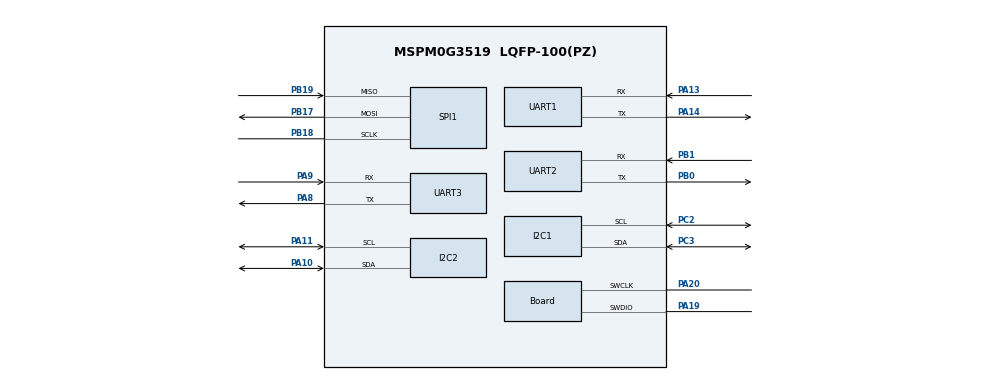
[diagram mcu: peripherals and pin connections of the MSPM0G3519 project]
/**
 * These arguments were used when this file was generated. They will be automatically applied on subsequent loads
 * via the GUI or CLI. Run CLI with '--help' for additional information on how to override these arguments.
 */
//@cliArgs --device "MSPM0G351X" --package "LQFP-100(PZ)" --part "Default"
//@v2CliArgs --device "MSPM0G3519" --package "LQFP-100(PZ)"
// @cliArgs --board /ti/boards/LP_MSPM0G3519 --rtos nortos

/**
 * Import the modules used in this configuration.
 */
const SYSCTL = scripting.addModule("/ti/driverlib/SYSCTL");
const GPIO   = scripting.addModule("/ti/driverlib/GPIO", {}, false);
const UART   = scripting.addModule("/ti/driverlib/UART", {}, false);
const I2C    = scripting.addModule("/ti/driverlib/I2C", {}, false);
const SPI    = scripting.addModule("/ti/driverlib/SPI", {}, false);
const GPIO1  = GPIO.addInstance();
const GPIO2  = GPIO.addInstance();
const GPIO3  = GPIO.addInstance();
const GPIO4  = GPIO.addInstance();
const GPIO5  = GPIO.addInstance();
const GPIO6  = GPIO.addInstance();
const GPIO7  = GPIO.addInstance();
const UART1  = UART.addInstance();
const UART2  = UART.addInstance();
const UART3  = UART.addInstance();
const I2C1   = I2C.addInstance();
const I2C2   = I2C.addInstance();
const SPI1   = SPI.addInstance();

/**
 * Write custom configuration values to the imported modules.
 */
SYSCTL.forceDefaultClkConfig = true;
SYSCTL.clockTreeEn           = true;

GPIO1.$name                          = "GPIO_LED_A";
GPIO1.port                           = "PORTA";
GPIO1.portSegment                    = "Upper";
GPIO1.associatedPins.create(2);
GPIO1.associatedPins[0].$name        = "LED1";
GPIO1.associatedPins[0].direction    = "OUTPUT";
GPIO1.associatedPins[0].initialValue = "SET";
GPIO1.associatedPins[0].assignedPin  = "27";
GPIO1.associatedPins[1].$name        = "LED2";
GPIO1.associatedPins[1].direction    = "OUTPUT";
GPIO1.associatedPins[1].initialValue = "SET";
GPIO1.associatedPins[1].assignedPin  = "26";

GPIO2.$name                          = "GPIO_BUZZER";
GPIO2.port                           = "PORTA";
GPIO2.portSegment                    = "Lower";
GPIO2.associatedPins.create(1);
GPIO2.associatedPins[0].$name        = "BUZZER";
GPIO2.associatedPins[0].direction    = "OUTPUT";
GPIO2.associatedPins[0].initialValue = "CLEARED";
GPIO2.associatedPins[0].assignedPin  = "12";

GPIO3.$name                               = "GPIO_BUTTON_C";
GPIO3.port                                = "PORTC";
GPIO3.portSegment                         = "Lower";
GPIO3.associatedPins.create(1);
GPIO3.associatedPins[0].$name             = "BUTTON1";
GPIO3.associatedPins[0].direction         = "INPUT";
GPIO3.associatedPins[0].internalResistor  = "PULL_UP";
GPIO3.associatedPins[0].assignedPin       = "9";

GPIO4.$name                               = "GPIO_BUTTON_B";
GPIO4.port                                = "PORTB";
GPIO4.portSegment                         = "Upper";
GPIO4.associatedPins.create(2);
GPIO4.associatedPins[0].$name             = "BUTTON2";
GPIO4.associatedPins[0].direction         = "INPUT";
GPIO4.associatedPins[0].internalResistor  = "PULL_UP";
GPIO4.associatedPins[0].assignedPin       = "20";
GPIO4.associatedPins[1].$name             = "BUTTON3";
GPIO4.associatedPins[1].direction         = "INPUT";
GPIO4.associatedPins[1].internalResistor  = "PULL_UP";
GPIO4.associatedPins[1].assignedPin       = "23";

GPIO5.$name                          = "GPIO_IMU_C";
GPIO5.port                           = "PORTC";
GPIO5.portSegment                    = "Lower";
GPIO5.associatedPins.create(3);
GPIO5.associatedPins[0].$name        = "ICM45686_INT1";
GPIO5.associatedPins[0].direction    = "INPUT";
GPIO5.associatedPins[0].assignedPin  = "6";
GPIO5.associatedPins[1].$name        = "ICM45686_CS";
GPIO5.associatedPins[1].direction    = "OUTPUT";
GPIO5.associatedPins[1].initialValue = "SET";
GPIO5.associatedPins[1].assignedPin  = "7";
GPIO5.associatedPins[2].$name        = "LIS3MDL_CS";
GPIO5.associatedPins[2].direction    = "OUTPUT";
GPIO5.associatedPins[2].initialValue = "SET";
GPIO5.associatedPins[2].assignedPin  = "8";

GPIO6.$name                          = "GPIO_IMU_A";
GPIO6.port                           = "PORTA";
GPIO6.portSegment                    = "Upper";
GPIO6.associatedPins.create(2);
GPIO6.associatedPins[0].$name        = "LIS3MDL_DRDY";
GPIO6.associatedPins[0].direction    = "INPUT";
GPIO6.associatedPins[0].assignedPin  = "22";
GPIO6.associatedPins[1].$name        = "ICM45686_INT2_FSYNC";
GPIO6.associatedPins[1].direction    = "INPUT";
GPIO6.associatedPins[1].assignedPin  = "31";

GPIO7.$name                          = "GPIO_LED_B";
GPIO7.port                           = "PORTB";
GPIO7.portSegment                    = "Upper";
GPIO7.associatedPins.create(1);
GPIO7.associatedPins[0].$name        = "LED3";
GPIO7.associatedPins[0].direction    = "OUTPUT";
GPIO7.associatedPins[0].initialValue = "SET";
GPIO7.associatedPins[0].assignedPin  = "27";

UART1.$name                    = "DEBUG_UART";
UART1.rxFifoThreshold          = "DL_UART_RX_FIFO_LEVEL_ONE_ENTRY";
UART1.targetBaudRate           = 115200;
UART1.enableFIFO               = true;
UART1.txFifoThreshold          = "DL_UART_TX_FIFO_LEVEL_3_4_EMPTY";
UART1.enableDMARX              = false;
UART1.enableDMATX              = false;
UART1.enabledInterrupts        = ["RX"];
UART1.peripheral.$assign       = "UART3";
UART1.peripheral.rxPin.$assign = "PA13";
UART1.peripheral.txPin.$assign = "PA14";

UART2.$name                    = "LORA_UART";
UART2.rxFifoThreshold          = "DL_UART_RX_FIFO_LEVEL_ONE_ENTRY";
UART2.targetBaudRate           = 115200;
UART2.enableFIFO               = true;
UART2.txFifoThreshold          = "DL_UART_TX_FIFO_LEVEL_3_4_EMPTY";
UART2.enableDMARX              = false;
UART2.enableDMATX              = false;
UART2.enabledInterrupts        = ["RX"];
UART2.peripheral.$assign       = "UART0";
UART2.peripheral.rxPin.$assign = "PB1";
UART2.peripheral.txPin.$assign = "PB0";

UART3.$name                    = "MOTOR_UART";
UART3.rxFifoThreshold          = "DL_UART_RX_FIFO_LEVEL_ONE_ENTRY";
UART3.targetBaudRate           = 115200;
UART3.enableFIFO               = true;
UART3.txFifoThreshold          = "DL_UART_TX_FIFO_LEVEL_3_4_EMPTY";
UART3.enableDMARX              = false;
UART3.enableDMATX              = false;
UART3.enabledInterrupts        = ["RX"];
UART3.peripheral.$assign       = "UART1";
UART3.peripheral.rxPin.$assign = "PA9";
UART3.peripheral.txPin.$assign = "PA8";

I2C1.basicEnableController     = true;
I2C1.basicControllerBusSpeed   = 400000;
I2C1.$name                     = "SENSOR_I2C";
I2C1.advAnalogGlitchFilter     = "DISABLED";
I2C1.peripheral.$assign        = "I2C2";
I2C1.peripheral.sclPin.$assign = "PC2";
I2C1.peripheral.sdaPin.$assign = "PC3";
I2C2.basicEnableController     = true;
I2C2.basicControllerBusSpeed   = 100000;
I2C2.$name                     = "MOTOR_I2C";
I2C2.advAnalogGlitchFilter     = "DISABLED";
I2C2.peripheral.$assign        = "I2C1";
I2C2.peripheral.sclPin.$assign = "PA11";
I2C2.peripheral.sdaPin.$assign = "PA10";

SPI1.$name                      = "IMU_SPI";
SPI1.targetBitRate              = 1000000;
SPI1.frameFormat                = "MOTO3";
SPI1.polarity                   = "1";
SPI1.phase                      = "1";
SPI1.peripheral.$assign         = "Any";
SPI1.peripheral.sclkPin.$assign = "PB18";
SPI1.peripheral.mosiPin.$assign = "PB17";
SPI1.peripheral.misoPin.$assign = "PB19";

const Board                       = scripting.addModule("/ti/driverlib/Board", {}, false);
Board.peripheral.$assign          = "DEBUGSS";
Board.peripheral.swclkPin.$assign = "PA20";
Board.peripheral.swdioPin.$assign = "PA19";

const ProjectConfig              = scripting.addModule("/ti/project_config/ProjectConfig", {}, false);
ProjectConfig.migrationCondition = true;
